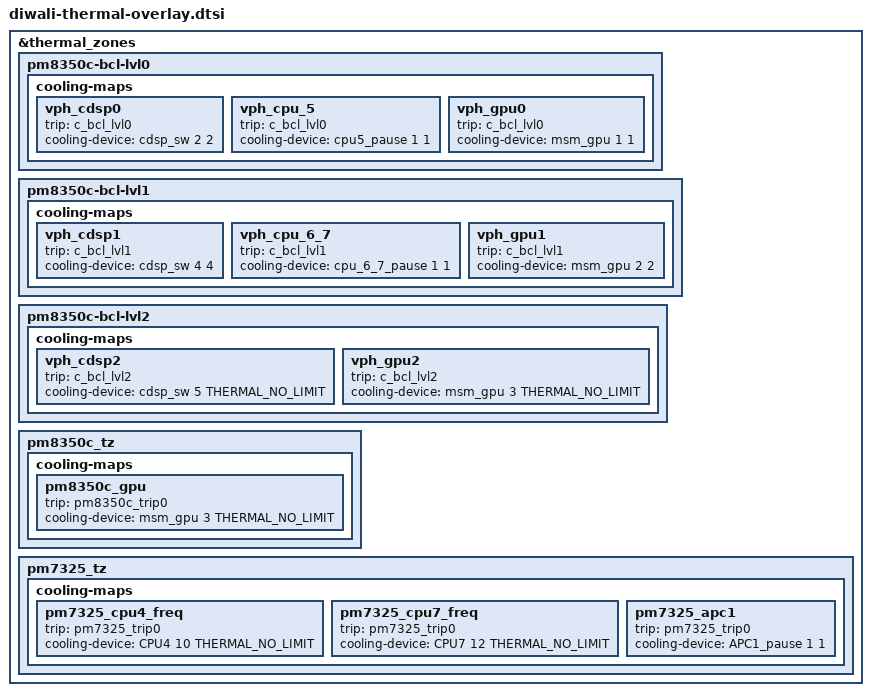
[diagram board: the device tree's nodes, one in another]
#include <dt-bindings/thermal/thermal_qti.h>

&thermal_zones {
	pm8350c-bcl-lvl0 {
		cooling-maps {
			vph_cdsp0 {
				trip = <&c_bcl_lvl0>;
				cooling-device = <&cdsp_sw 2 2>;
			};

			vph_cpu_5 {
				trip = <&c_bcl_lvl0>;
				cooling-device = <&cpu5_pause 1 1>;
			};

			vph_gpu0 {
				trip = <&c_bcl_lvl0>;
				cooling-device = <&msm_gpu 1 1>;
			};
		};
	};

	pm8350c-bcl-lvl1 {
		cooling-maps {
			vph_cdsp1 {
				trip = <&c_bcl_lvl1>;
				cooling-device = <&cdsp_sw 4 4>;
			};

			vph_cpu_6_7 {
				trip = <&c_bcl_lvl1>;
				cooling-device = <&cpu_6_7_pause 1 1>;
			};

			vph_gpu1 {
				trip = <&c_bcl_lvl1>;
				cooling-device = <&msm_gpu 2 2>;
			};
		};
	};

	pm8350c-bcl-lvl2 {
		cooling-maps {
			vph_cdsp2 {
				trip = <&c_bcl_lvl2>;
				cooling-device = <&cdsp_sw 5 THERMAL_NO_LIMIT>;
			};

			vph_gpu2 {
				trip = <&c_bcl_lvl2>;
				cooling-device = <&msm_gpu 3 THERMAL_NO_LIMIT>;
			};
		};
	};

	pm8350c_tz {
		cooling-maps {
			pm8350c_gpu {
				trip = <&pm8350c_trip0>;
				cooling-device = <&msm_gpu 3 THERMAL_NO_LIMIT>;
			};
		};
	};

	pm7325_tz {
		cooling-maps {
			pm7325_cpu4_freq {
				trip = <&pm7325_trip0>;
				cooling-device = <&CPU4 10 THERMAL_NO_LIMIT>;
			};

			pm7325_cpu7_freq {
				trip = <&pm7325_trip0>;
				cooling-device = <&CPU7 12 THERMAL_NO_LIMIT>;
			};

			pm7325_apc1 {
				trip = <&pm7325_trip0>;
				cooling-device = <&APC1_pause 1 1>;
			};
		};
	};
};
